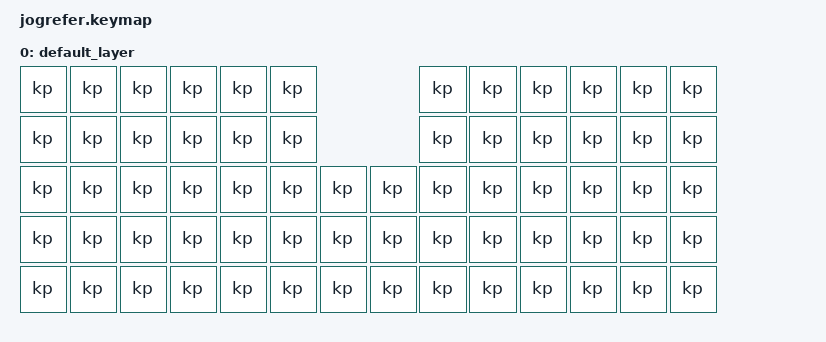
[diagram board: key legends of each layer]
#include <behaviors.dtsi>
#include <dt-bindings/zmk/keys.h>

/ {
	keymap {
		compatible = "zmk,keymap";

		default_layer {
			bindings = <

//				╭────────────────────╮         ╭────────────────────╮
//				│  ×  1  2  3  4  5	│         │  6  7  8  9  0  \  │
//				│  ⭾  F  M  N  G  X	╰──╮   ╭──╯  W  V  B  P  Y  -  │
//				│  ⇪  D  T  R  S  L  Ç  │   │  ⏍  U  A  E  O  I  +	 │
//				│  ´  Z  Q  H  C  K  [  │   │  <  Ñ  J  ,  .  /  ⇪  │
//				│  ⌘  ⌗  ⏍  ⌥  ␣  ←  ]	│   │  ⌘  ↩︎  ␣  ←  ↑  →  ↓  │
//				╰───────────────────────╯   ╰───────────────────────╯

				&kp  &kp  &kp  &kp  &kp  &kp            &kp  &kp  &kp  &kp  &kp  &kp
				&kp  &kp  &kp  &kp  &kp  &kp            &kp  &kp  &kp  &kp  &kp  &kp
				&kp  &kp  &kp  &kp  &kp  &kp  &kp  &kp  &kp  &kp  &kp  &kp  &kp  &kp
				&kp  &kp  &kp  &kp  &kp  &kp  &kp  &kp  &kp  &kp  &kp  &kp  &kp  &kp
				&kp  &kp  &kp  &kp  &kp  &kp  &kp  &kp  &kp  &kp  &kp  &kp  &kp  &kp

			>;
		};
	};
};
